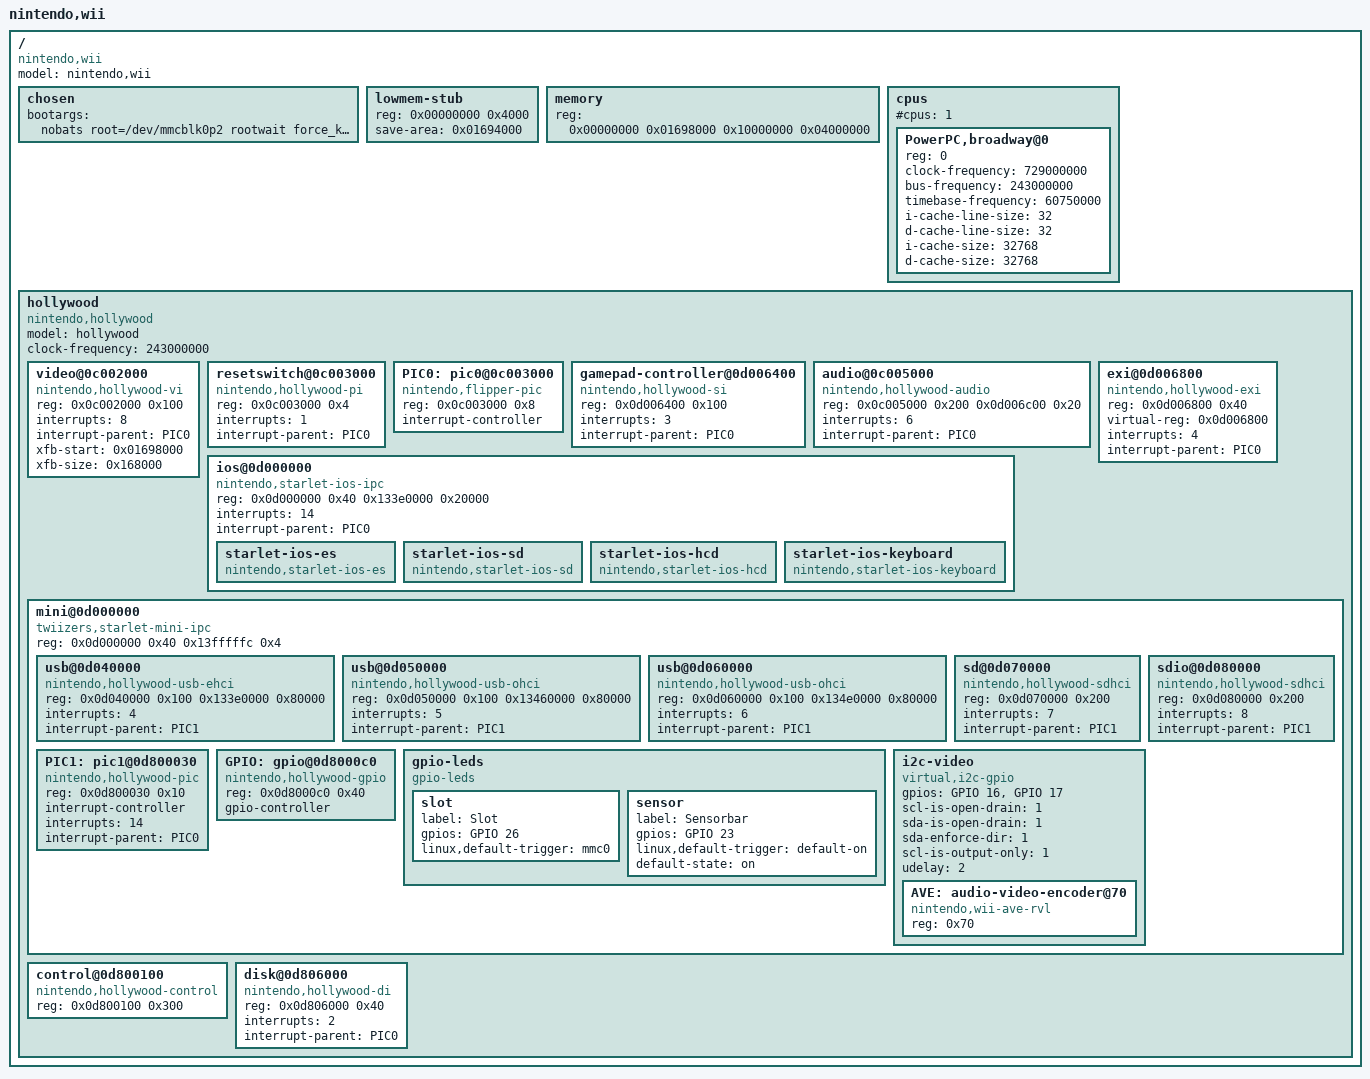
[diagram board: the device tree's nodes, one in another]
/*
 * arch/powerpc/boot/dts/wii.dts
 *
 * Nintendo Wii platform device tree source
 * Copyright (C) 2008-2009 The GameCube Linux Team
 * Copyright (C) 2008,2009 Albert Herranz
 *
 * This program is free software; you can redistribute it and/or
 * modify it under the terms of the GNU General Public License
 * as published by the Free Software Foundation; either version 2
 * of the License, or (at your option) any later version.
 *
 */

/dts-v1/;

/memreserve/ 0x10000000 0x0004000;	/* DSP RAM */
/memreserve/ 0x01694000 0x0004000;	/* lowmem stub save area */
/memreserve/ 0x01698000 0x0168000;	/* framebuffer, see video@0c002000 */
/memreserve/ 0x01800000 0xe800000;	/* memory hole */

/ {
	model = "nintendo,wii";
	compatible = "nintendo,wii";
	#address-cells = <1>;
	#size-cells = <1>;

	chosen {
		/* ramdisk example */
		//bootargs = "nobats root=/dev/ram0 video=gcnfb ip=on force_keyboard_port=4";

		/* nfsroot example */
		//bootargs = "nobats root=/dev/nfs nfsroot=192.168.001.253:/nfsroot/cube ip=on video=gcnfb:tv=NTSC force_keyboard_port=4";

		/* root filesystem on 2nd partition of SD card ("Whiite" style)  */
		bootargs = "nobats root=/dev/mmcblk0p2 rootwait force_keyboard_port=4 video=gcnfb:60Hz tv=auto loader=mini quite nostalgic_mini_placeholder_for_additional_kernel_options_appended_here_using_a_hex_editor";
		//bootargs = "nobats root=/dev/rvlsda2 rootwait force_keyboard_port=4 video=gcnfb:60Hz tv=auto loader=ios quite nostalgic_ios_placeholder_for_additional_kernel_options_appended_here_using_a_hex_editor";

	};

	lowmem-stub {
		reg = <0x00000000 0x4000>;
		save-area = <0x01694000>;	/* must be memreserve'd */
	};

	memory {
		device_type = "memory";
		reg = <0x00000000 0x01698000	/* MEM1 24MB 1T-SRAM */
		       0x10000000 0x04000000>;	/* MEM2 64MB GDDR3 */
	};

	cpus {
		#cpus = <1>;
		#address-cells = <1>;
		#size-cells = <0>;

		PowerPC,broadway@0 {
			device_type = "cpu";
			reg = <0>;
			clock-frequency = <729000000>; /* 729MHz */
			bus-frequency = <243000000>; /* 243MHz core-to-bus 3x */
			timebase-frequency = <60750000>; /* 243MHz / 4 */
			i-cache-line-size = <32>;
			d-cache-line-size = <32>;
			i-cache-size = <32768>;
			d-cache-size = <32768>;
		};
	};

	/* devices contained in the hollywood chipset */
	hollywood {
		#address-cells = <1>;
		#size-cells = <1>;
		#interrupt-cells = <1>;
		model = "hollywood";
		compatible = "nintendo,hollywood";
		clock-frequency = <243000000>; /* 243MHz */
		ranges = <0x0c000000 0x0c000000 0x00010000
			  0x0d000000 0x0d000000 0x00010000
			  0x0d040000 0x0d040000 0x00050000
			  0x0d800000 0x0d800000 0x00007000
			  0x133e0000 0x133e0000 0x00c20000>;

		video@0c002000 {
			compatible = "nintendo,hollywood-vi",
					"nintendo,flipper-vi";
			reg = <0x0c002000 0x100>;
			interrupts = <8>;
			interrupt-parent = <&PIC0>;
			xfb-start = <0x01698000>; /* end-of-mem1 - xfb-size */
			xfb-size = <0x168000>;    /* 640x576x2 x 2 bytes */
		};

		resetswitch@0c003000 {
			compatible = "nintendo,hollywood-pi",
					"nintendo,flipper-pi";
			reg = <0x0c003000 0x4>;
			interrupts = <1>;
			interrupt-parent = <&PIC0>;
		};

		PIC0: pic0@0c003000 {
			#interrupt-cells = <1>;
			compatible = "nintendo,flipper-pic";
			reg = <0x0c003000 0x8>;
			interrupt-controller;
		};

		gamepad-controller@0d006400 {
			compatible = "nintendo,hollywood-si",
					"nintendo,flipper-si";
			reg = <0x0d006400 0x100>;
			interrupts = <3>;
			interrupt-parent = <&PIC0>;
		};

		audio@0c005000 {
			compatible = "nintendo,hollywood-audio";
			reg = <0x0c005000 0x200		/* DSP */
			       0x0d006c00 0x20>;	/* AI */
			interrupts = <6>;
			interrupt-parent = <&PIC0>;
		};

		/* External Interface bus */
		exi@0d006800 {
			compatible = "nintendo,hollywood-exi",
					"nintendo,flipper-exi";
			#address-cells = <1>;
			#size-cells = <1>;
			reg = <0x0d006800 0x40>;
			virtual-reg = <0x0d006800>;
			interrupts = <4>;
			interrupt-parent = <&PIC0>;
		};

	    /*
	     * Firmware interfaces accessible through Nintendo IOS IPC.
	     */
	    ios@0d000000 {
		compatible = "nintendo,starlet-ios-ipc";
		reg = <0x0d000000 0x40		/* IPC */
		       0x133e0000 0x20000>;	/* MEM2 ioh 128K */
		interrupts = <14>;
		interrupt-parent = <&PIC0>;

		starlet-ios-es {
			compatible = "nintendo,starlet-ios-es";
		};

		starlet-ios-sd {
			compatible = "nintendo,starlet-ios-sd";
		};

		starlet-ios-hcd {
			compatible = "nintendo,starlet-ios-hcd";
		};

		starlet-ios-keyboard {
			compatible = "nintendo,starlet-ios-keyboard";
		};
	    };

	    /*
	     * Hardware accessible through Team Twiizers 'mini' firmware
	     * replacement for Starlet.
	     */
	    mini@0d000000 {
		#address-cells = <1>;
		#size-cells = <1>;
		#interrupt-cells = <1>;
		compatible = "twiizers,starlet-mini-ipc";
		reg = <0x0d000000 0x40	/* IPC */
		       0x13fffffc 0x4>;	/* mini header pointer */

		ranges = <0x0d040000 0x0d040000 0x00050000
			  0x0d800000 0x0d800000 0x00007000
			  0x133e0000 0x133e0000 0x00c20000>;
				  
		usb@0d040000 {
			compatible = "nintendo,hollywood-usb-ehci",
					"usb-ehci";
			reg = <0x0d040000 0x100
			       0x133e0000 0x80000>; /* 512 KB */
			interrupts = <4>;
			interrupt-parent = <&PIC1>;
		};

		usb@0d050000 {
			compatible = "nintendo,hollywood-usb-ohci",
					"usb-ohci";
			reg = <0x0d050000 0x100
			       0x13460000 0x80000>; /* 512 KB */
			interrupts = <5>;
			interrupt-parent = <&PIC1>;
		};

		usb@0d060000 {
			compatible = "nintendo,hollywood-usb-ohci",
					"usb-ohci";
			reg = <0x0d060000 0x100
			       0x134e0000 0x80000>; /* 512 KB */
			interrupts = <6>;
			interrupt-parent = <&PIC1>;
		};

		sd@0d070000 {
			compatible = "nintendo,hollywood-sdhci",
					"sdhci";
			reg = <0x0d070000 0x200>;
			interrupts = <7>;
			interrupt-parent = <&PIC1>;
		};

		sdio@0d080000 {
			compatible = "nintendo,hollywood-sdhci",
					"sdhci";
			reg = <0x0d080000 0x200>;
			interrupts = <8>;
			interrupt-parent = <&PIC1>;
		};

		PIC1: pic1@0d800030 {
			#interrupt-cells = <1>;
			compatible = "nintendo,hollywood-pic";
			reg = <0x0d800030 0x10>;
			interrupt-controller;
			interrupts = <14>;
			interrupt-parent = <&PIC0>;
		};

		GPIO: gpio@0d8000c0 {
			#gpio-cells = <2>;
			compatible = "nintendo,hollywood-gpio";
			reg = <0x0d8000c0 0x40>;
			gpio-controller;

		};
	
			gpio-leds {
				compatible = "gpio-leds";
			
				slot {
					label = "Slot";
					gpios = <&GPIO 26 0>;
					linux,default-trigger = "mmc0";
				};

				sensor {
					label = "Sensorbar";
					gpios = <&GPIO 23 0>;
					linux,default-trigger = "default-on";
					default-state="on";
				};
			
			};

			i2c-video {
				#address-cells = <1>;
				#size-cells = <0>;
					compatible = "virtual,i2c-gpio";

					gpios = <&GPIO 16 0		/* 31-15 */
							&GPIO 17 0>;	/* 31-14 */
			        scl-is-open-drain = <1>;
			        sda-is-open-drain = <1>;
			        sda-enforce-dir = <1>;
					scl-is-output-only = <1>;
					udelay = <2>;

			        AVE: audio-video-encoder@70 {
			                compatible = "nintendo,wii-ave-rvl";
			                reg = <0x70>;
					};
			};
		};

		control@0d800100 {
			compatible = "nintendo,hollywood-control";
			reg = <0x0d800100 0x300>;
		};

		disk@0d806000 {
			compatible = "nintendo,hollywood-di";
			reg = <0x0d806000 0x40>;
			interrupts = <2>;
			interrupt-parent = <&PIC0>;
		};
	};
};

